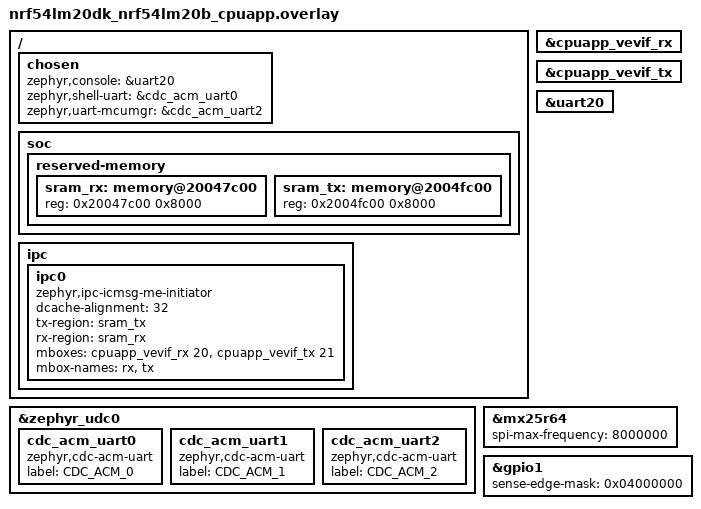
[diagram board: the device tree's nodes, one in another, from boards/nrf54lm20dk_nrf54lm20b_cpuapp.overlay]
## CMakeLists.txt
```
#
# Copyright (c) 2022 Nordic Semiconductor ASA
#
# SPDX-License-Identifier: Apache-2.0
#

cmake_minimum_required(VERSION 3.20.0)

find_package(Zephyr REQUIRED HINTS $ENV{ZEPHYR_BASE})

project(ipc_service)

FILE(GLOB app_sources src/*.c)
target_sources(app PRIVATE ${app_sources})

zephyr_include_directories(include memfault_config)
```

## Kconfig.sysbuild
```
# Copyright 2023 Nordic Semiconductor ASA
#
# SPDX-License-Identifier: Apache-2.0

source "share/sysbuild/Kconfig"

config NET_CORE_BOARD
string
	default "$(BOARD)/nrf5340/cpunet" if $(BOARD) = "nrf5340dk"
	default "$(BOARD)/nrf5340/cpunet" if $(BOARD) = "nrf5340bsim"
	default "$(BOARD)/nrf54h20/cpurad" if $(BOARD) = "nrf54h20dk"
	default "nrf54lm20dk/nrf54lm20b/cpuflpr" if "$(BOARD)/$(BOARD_QUALIFIERS)" = "nrf54lm20dk/nrf54lm20b/cpuapp"
```

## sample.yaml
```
sample:
  name: IPC multi-endpoint MDS + FLPR
common:
  sysbuild: true
  extra_args: multi_endpoint_SNIPPET="nordic-flpr;mds-flpr"
  tags: ipc bluetooth mcuboot mcumgr
tests:
  sample.ipc.multi_endpoint.mds_flpr.nrf54lm20b:
    platform_allow:
      - nrf54lm20dk/nrf54lm20b/cpuapp
    integration_platforms:
      - nrf54lm20dk/nrf54lm20b/cpuapp
    harness: console
    harness_config:
      type: multi_line
      ordered: false
      regex:
        - "Starting Bluetooth Memfault sample with FLPR IPC"
        - "APP version:"
        - "Bluetooth initialized"
        - "Advertising successfully started"
    timeout: 60

  sample.ipc.multi_endpoint.mds_flpr.nrf54lm20b.build:
    platform_allow:
      - nrf54lm20dk/nrf54lm20b/cpuapp
    integration_platforms:
      - nrf54lm20dk/nrf54lm20b/cpuapp
    build_only: true
    timeout: 600

  sample.ipc.multi_endpoint.mds_flpr.nrf54lm20b.ota_ble:
    platform_allow:
      - nrf54lm20dk/nrf54lm20b/cpuapp
    integration_platforms:
      - nrf54lm20dk/nrf54lm20b/cpuapp
    harness: pytest
    harness_config:
      fixture: usb_hci
      pytest_root:
        - "pytest/test_ota_ble.py"
    slow: true
    timeout: 600
```

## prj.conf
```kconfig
CONFIG_NCS_SAMPLES_DEFAULTS=y

CONFIG_PRINTK=y

CONFIG_IPC_SERVICE=y
CONFIG_MBOX=y
CONFIG_IPC_SERVICE_LOG_LEVEL_INF=y

CONFIG_BT=y
# BT shell for bt advertise / id-show / etc. Connection dumps used to wedge CDC0
# shell (IRQ TXDONE wait forever). Mitigations below: blocking shell TX + CDC WQ.
CONFIG_BT_SHELL=y
CONFIG_BT_SMP=y
CONFIG_BT_PERIPHERAL=y
CONFIG_BT_DEVICE_NAME="Nordic_Memfault"
CONFIG_BT_PRIVACY=y
# Advertise with identity address (see BT_LE_ADV_OPT_USE_IDENTITY in main.c) so
# scanners see a stable MAC; privacy IRK still used once bonded.
# Allow Windows/bleak to re-pair over an existing Just Works bond (repair after
# remove-on-host or stale LTK) without requiring bt clear all on the DK.
CONFIG_BT_SMP_ALLOW_UNAUTH_OVERWRITE=y
# Windows/iOS Just Works bonding (no display/keyboard). MITM enforcement rejects
# that pairing so bonds do not stick and phones treat each connect as a new device.
CONFIG_BT_SMP_ENFORCE_MITM=n

CONFIG_BT_BAS=y
CONFIG_BT_MDS=y

CONFIG_BT_CTLR_PHY_2M=y
CONFIG_BT_BUF_ACL_RX_SIZE=251
CONFIG_BT_L2CAP_TX_MTU=247
CONFIG_BT_BUF_ACL_TX_SIZE=251
CONFIG_BT_CTLR_DATA_LENGTH_MAX=251

CONFIG_LOG=y
CONFIG_LOG_PRINTK=n
CONFIG_LOG_DEFAULT_LEVEL=2
CONFIG_LOG_MODE_DEFERRED=y
CONFIG_LOG_MODE_OVERFLOW=y
CONFIG_LOG_BACKEND_RTT=n

CONFIG_SHELL=y
CONFIG_SENSOR_SHELL=n
CONFIG_DK_LIBRARY=y
# Keep bt_shell usable on CDC0: blocking TX avoids forever wait on UART IRQ
# TXDONE when BT conn callbacks print Connected/LMP/Features into the shell.
CONFIG_SHELL_BACKEND_SERIAL_FORCE_TX_BLOCKING_MODE=y
CONFIG_SHELL_BACKEND_SERIAL_TX_RING_BUFFER_SIZE=256

CONFIG_HEAP_MEM_POOL_SIZE=8192

CONFIG_MEMFAULT=y
CONFIG_MEMFAULT_SHELL=y
CONFIG_MEMFAULT_LOGGING_ENABLE=y
CONFIG_MEMFAULT_LOG_LEVEL_INF=y

CONFIG_MEMFAULT_NCS_PROJECT_KEY="PRDDdY3Idi9MqFBLK1U11AyuNoZoaqPj"
CONFIG_MEMFAULT_NCS_DEVICE_ID_STATIC=y
CONFIG_MEMFAULT_NCS_DEVICE_ID="nrf-ble-testdevice"
# Firmware version comes from the sample VERSION file (APP_VERSION_TWEAK_STRING).
CONFIG_MEMFAULT_NCS_FW_VERSION_STATIC=y
CONFIG_MEMFAULT_NCS_BT_METRICS=y
CONFIG_MEMFAULT_MCUMGR_GRP=y

CONFIG_BT_SETTINGS=y
CONFIG_FLASH=y
CONFIG_FLASH_PAGE_LAYOUT=y
CONFIG_FLASH_MAP=y
CONFIG_SETTINGS=y
# nRF54L Series: use ZMS (not NVS) as the Settings backend for bonding/CCCs.
CONFIG_ZMS=y
CONFIG_SETTINGS_ZMS=y

# SPI00 MX25R64 for spiflash CLI (OTA secondary remains on internal RRAM)
CONFIG_GPIO=y
CONFIG_SPI=y
CONFIG_SPI_NOR=y
CONFIG_SPI_NOR_FLASH_LAYOUT_PAGE_SIZE=4096
CONFIG_NORDIC_QSPI_NOR=n

# Sleep shell: System OFF + reset-cause decode + device suspend before off
CONFIG_POWEROFF=y
CONFIG_HWINFO=y
CONFIG_PM_DEVICE=y

# BLE + UART MCUmgr OTA (same coupled app_update.bin).
# UART SMP is on USB CDC2 only; CDC1 stays FLPR logs.
CONFIG_NCS_SAMPLE_MCUMGR_BT_OTA_DFU=y
CONFIG_NCS_SAMPLE_MCUMGR_BT_OTA_DFU_SPEEDUP=y
CONFIG_MCUMGR_GRP_ZBASIC_STORAGE_ERASE=n
# CONFIG_MCUBOOT_IMGTOOL_SIGN_VERSION defaults to APP_VERSION_TWEAK_STRING from VERSION.
CONFIG_UART_MCUMGR=y
CONFIG_MCUMGR_TRANSPORT_UART=y
# Larger UART SMP frames + more line buffers so USB CDC DFU does not stall when
# the host fills NETBUF-sized chunks (default RX was 128*2).
CONFIG_MCUMGR_TRANSPORT_UART_MTU=1024
CONFIG_UART_MCUMGR_RX_BUF_SIZE=128
CONFIG_UART_MCUMGR_RX_BUF_COUNT=16
CONFIG_BASE64=y

# Triple CDC ACM (USB device on cpuapp). Stock CDC_ACM_SERIAL_* boot helper
# is off — src/usb_cdc_triple.c registers CDC0/1/2 explicitly.
CONFIG_SERIAL=y
CONFIG_CONSOLE=y
CONFIG_UART_CONSOLE=y
CONFIG_UART_LINE_CTRL=y
CONFIG_USB_DEVICE_STACK_NEXT=y
CONFIG_USBD_CDC_ACM_CLASS=y
CONFIG_CDC_ACM_SERIAL_INITIALIZE_AT_BOOT=n
# Dedicated CDC workqueue so shell/BT prints do not deadlock the USB path.
CONFIG_USBD_CDC_ACM_WORKQUEUE=y
CONFIG_USBD_CDC_ACM_STACK_SIZE=2048
# Host control transfers can request up to ~4 KiB (seen as udc alloc 4095 on ep 0x80).
# Three CDCs need more outstanding request buffers than dual-CDC defaults.
CONFIG_UDC_BUF_POOL_SIZE=12288
CONFIG_UDC_BUF_COUNT=48
```

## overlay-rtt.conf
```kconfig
# Optional: free uart20 - printk/boot on RTT; shell + LOG stay on USB CDC0.
# Use with boards/nrf54lm20dk_nrf54lm20b_cpuapp_rtt.overlay (see just build-rtt).

CONFIG_USE_SEGGER_RTT=y
CONFIG_RTT_CONSOLE=y
CONFIG_UART_CONSOLE=n

# Do not block boot if no RTT Viewer is attached (default mode is skip).
CONFIG_SEGGER_RTT_MODE_NO_BLOCK_SKIP=y
# Avoid sleep/retry delays when the RTT host is absent.
CONFIG_RTT_TX_RETRY_CNT=0

# Keep printk on RTT; application LOG continues via shell backend on CDC0.
CONFIG_LOG_BACKEND_RTT=n
CONFIG_LOG_PRINTK=n
```

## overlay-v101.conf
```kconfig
# Deprecated: bump the sample VERSION file instead (VERSION_MAJOR/MINOR/PATCHLEVEL/TWEAK).
# Kept empty so older docs/scripts that still pass EXTRA_CONF_FILE=overlay-v101.conf do not fail.
```

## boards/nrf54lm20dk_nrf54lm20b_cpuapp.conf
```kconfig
# SPI00 MX25R64 (jedec,spi-nor) — plain SPI, not SQSPI
CONFIG_GPIO=y
CONFIG_SPI=y
CONFIG_SPI_NOR=y
CONFIG_SPI_NOR_FLASH_LAYOUT_PAGE_SIZE=4096
CONFIG_NORDIC_QSPI_NOR=n
```

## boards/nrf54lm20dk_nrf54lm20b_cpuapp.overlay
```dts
/ {
	chosen {
		/*
		 * App printk/LOG → debugger VCOM (uart20).
		 * USB CDC0 → shell
		 * USB CDC1 → FLPR log forward (see flpr_ipc.c)
		 * USB CDC2 → MCUmgr UART SMP DFU (CONFIG_MCUMGR_TRANSPORT_UART)
		 *
		 * Stock cdc_acm_serial boot helper only registers chosen CDCs;
		 * this sample uses src/usb_cdc_triple.c so CDC1 is registered
		 * even though it is not a chosen backend.
		 */
		zephyr,console = &uart20;
		zephyr,shell-uart = &cdc_acm_uart0;
		zephyr,uart-mcumgr = &cdc_acm_uart2;
	};

	soc {
		reserved-memory {
			#address-cells = <1>;
			#size-cells = <1>;

			sram_rx: memory@20047c00 {
				reg = <0x20047c00 0x8000>;
			};

			sram_tx: memory@2004fc00 {
				reg = <0x2004fc00 0x8000>;
			};
		};
	};

	ipc {
		ipc0: ipc0 {
			compatible = "zephyr,ipc-icmsg-me-initiator";
			dcache-alignment = <32>;
			tx-region = <&sram_tx>;
			rx-region = <&sram_rx>;
			mboxes = <&cpuapp_vevif_rx 20>, <&cpuapp_vevif_tx 21>;
			mbox-names = "rx", "tx";
			status = "okay";
		};
	};
};

&cpuapp_vevif_rx {
	status = "okay";
};

&cpuapp_vevif_tx {
	status = "okay";
};

&uart20 {
	status = "okay";
};

&zephyr_udc0 {
	cdc_acm_uart0: cdc_acm_uart0 {
		compatible = "zephyr,cdc-acm-uart";
		label = "CDC_ACM_0";
	};

	cdc_acm_uart1: cdc_acm_uart1 {
		compatible = "zephyr,cdc-acm-uart";
		label = "CDC_ACM_1";
	};

	cdc_acm_uart2: cdc_acm_uart2 {
		compatible = "zephyr,cdc-acm-uart";
		label = "CDC_ACM_2";
	};
};

/* SPI00 MX25R64 for shell CLI only — OTA secondary stays on internal RRAM. */
&mx25r64 {
	status = "okay";
	spi-max-frequency = <8000000>;
};

/* Button0 (sw0) on P1.26 — PORT sense for System OFF / idle GPIO wake. */
&gpio1 {
	sense-edge-mask = <0x04000000>; /* BIT(26) */
};
```

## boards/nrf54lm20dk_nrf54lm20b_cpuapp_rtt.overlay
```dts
/*
 * Optional RTT boot console - apply with overlay-rtt.conf (just build-rtt).
 *
 * - Disables debugger uart20 (frees the UART peripheral / pins)
 * - printk / early boot go to SEGGER RTT (no USB wait, non-blocking)
 * - Shell remains USB CDC0; FLPR logs CDC1; MCUmgr DFU CDC2
 *   (from nrf54lm20dk_nrf54lm20b_cpuapp.overlay)
 */

/ {
	chosen {
		/delete-property/ zephyr,console;
	};
};

&uart20 {
	status = "disabled";
};
```

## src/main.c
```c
#include "flpr_ipc.h"
#include "sleep_shell.h"

#include <zephyr/kernel.h>
#include <zephyr/dfu/mcuboot.h>

#include <zephyr/bluetooth/bluetooth.h>
#include <zephyr/bluetooth/conn.h>
#include <zephyr/bluetooth/hci.h>
#include <zephyr/bluetooth/services/bas.h>

#include <bluetooth/services/mds.h>

#include <zephyr/settings/settings.h>

#include <dk_buttons_and_leds.h>

#include <memfault/metrics/metrics.h>
#include <memfault/core/trace_event.h>

#define DEVICE_NAME     CONFIG_BT_DEVICE_NAME
#define DEVICE_NAME_LEN (sizeof(DEVICE_NAME) - 1)

#define RUN_STATUS_LED DK_LED1
#define CON_STATUS_LED DK_LED2

#define RUN_LED_BLINK_INTERVAL 1000

/* Stable advertiser address so nRF Connect / Memfault see the same device after
 * disconnect (default privacy RPA rotation looks like a new peripheral).
 */
static const struct bt_le_adv_param *const adv_param =
	BT_LE_ADV_PARAM(BT_LE_ADV_OPT_CONN | BT_LE_ADV_OPT_USE_IDENTITY,
			BT_GAP_ADV_FAST_INT_MIN_2, BT_GAP_ADV_FAST_INT_MAX_2, NULL);

static const struct bt_data ad[] = {
	BT_DATA_BYTES(BT_DATA_FLAGS, (BT_LE_AD_GENERAL | BT_LE_AD_NO_BREDR)),
	BT_DATA_BYTES(BT_DATA_UUID128_ALL, BT_UUID_MDS_VAL),
};

static const struct bt_data sd[] = {
	BT_DATA(BT_DATA_NAME_COMPLETE, DEVICE_NAME, DEVICE_NAME_LEN),
};

static struct bt_conn *mds_conn;
static struct k_work adv_work;

static void bas_work_handler(struct k_work *work);

static K_WORK_DELAYABLE_DEFINE(bas_work, bas_work_handler);

static void security_changed(struct bt_conn *conn, bt_security_t level,
			     enum bt_security_err err)
{
	char addr[BT_ADDR_LE_STR_LEN];

	bt_addr_le_to_str(bt_conn_get_dst(conn), addr, sizeof(addr));

	if (!err) {
		printk("Security changed: %s level %u\n", addr, level);
	} else {
		printk("Security failed: %s level %u err %d %s\n", addr, level, err,
		       bt_security_err_to_str(err));
	}

	if (level >= BT_SECURITY_L2) {
		if (!mds_conn) {
			mds_conn = conn;
		}
	}
}

static void adv_work_handler(struct k_work *work)
{
	int err = bt_le_adv_start(adv_param, ad, ARRAY_SIZE(ad), sd, ARRAY_SIZE(sd));

	if (err) {
		printk("Advertising failed to start (err %d)\n", err);
		return;
	}

	printk("Advertising successfully started\n");
}

static void advertising_start(void)
{
	k_work_submit(&adv_work);
}

static void disconnected(struct bt_conn *conn, uint8_t reason)
{
	printk("Disconnected, reason 0x%02x %s\n", reason, bt_hci_err_to_str(reason));

	dk_set_led_off(CON_STATUS_LED);

	if (conn == mds_conn) {
		mds_conn = NULL;
	}
	/* Do not restart advertising here: with CONFIG_BT_MAX_CONN=1 the conn
	 * object is still held until recycled_cb(). That is where we advertise.
	 */
}

static void recycled_cb(void)
{
	printk("Connection object available from previous conn. Disconnect is complete!\n");
	advertising_start();
}

static void connected(struct bt_conn *conn, uint8_t conn_err)
{
	char addr[BT_ADDR_LE_STR_LEN];

	if (conn_err) {
		printk("Connection failed, err 0x%02x %s\n", conn_err, bt_hci_err_to_str(conn_err));
		/* Failed connect still frees the slot via recycled → advertising. */
		return;
	}

	bt_addr_le_to_str(bt_conn_get_dst(conn), addr, sizeof(addr));
	printk("Connected %s\n", addr);

	dk_set_led_on(CON_STATUS_LED);
}

BT_CONN_CB_DEFINE(conn_callbacks) = {
	.connected        = connected,
	.disconnected     = disconnected,
	.security_changed = security_changed,
	.recycled         = recycled_cb,
};

static void pairing_complete(struct bt_conn *conn, bool bonded)
{
	char addr[BT_ADDR_LE_STR_LEN];

	bt_addr_le_to_str(bt_conn_get_dst(conn), addr, sizeof(addr));

	printk("Pairing completed: %s, bonded: %d\n", addr, bonded);
}

static void pairing_failed(struct bt_conn *conn, enum bt_security_err reason)
{
	char addr[BT_ADDR_LE_STR_LEN];

	bt_addr_le_to_str(bt_conn_get_dst(conn), addr, sizeof(addr));

	printk("Pairing failed conn: %s, reason %d %s\n", addr, reason,
	       bt_security_err_to_str(reason));
}

static struct bt_conn_auth_info_cb conn_auth_info_callbacks = {
	.pairing_complete = pairing_complete,
	.pairing_failed = pairing_failed
};

static void auth_cancel(struct bt_conn *conn)
{
	char addr[BT_ADDR_LE_STR_LEN];

	bt_addr_le_to_str(bt_conn_get_dst(conn), addr, sizeof(addr));

	printk("Pairing cancelled: %s\n", addr);
}

static struct bt_conn_auth_cb conn_auth_callbacks = {
	.cancel = auth_cancel,
};

static bool mds_access_enable(struct bt_conn *conn)
{
	if (mds_conn && (conn == mds_conn)) {
		return true;
	}

	return false;
}

static const struct bt_mds_cb mds_cb = {
	.access_enable = mds_access_enable,
};

static void button_handler(uint32_t button_state, uint32_t has_changed)
{
	static bool time_measure_start;

	int err;
	uint32_t buttons = button_state & has_changed;

	sleep_shell_button_notify(buttons);

	if (buttons & DK_BTN1_MSK) {
		time_measure_start = !time_measure_start;

		if (time_measure_start) {
			err = MEMFAULT_METRIC_TIMER_START(button_elapsed_time_ms);
			if (err) {
				printk("Failed to start memfault metrics timer: %d\n", err);
			}
		} else {
			err = MEMFAULT_METRIC_TIMER_STOP(button_elapsed_time_ms);
			if (err) {
				printk("Failed to stop memfault metrics: %d\n", err);
			}

			memfault_metrics_heartbeat_debug_trigger();
		}
	}

	if (has_changed & DK_BTN2_MSK) {
		bool pressed = (buttons & DK_BTN2_MSK) ? 1 : 0;

		MEMFAULT_TRACE_EVENT_WITH_LOG(button_state_changed, "Button state: %u",
					      pressed);

		printk("button_state_changed event has been tracked, button state: %u\n",
		       pressed);
	}

	if (buttons & DK_BTN3_MSK) {
		err = MEMFAULT_METRIC_ADD(button_press_count, 1);
		if (err) {
			printk("Failed to increase button_press_count metric: %d\n", err);
		} else {
			printk("button_press_count metric increased\n");
		}
	}

	if (buttons & DK_BTN4_MSK) {
		volatile uint32_t i;

		printk("Division by zero will now be triggered\n");
#pragma GCC diagnostic push
#pragma GCC diagnostic ignored "-Wdiv-by-zero"
		i = 1 / 0;
#pragma GCC diagnostic pop
		ARG_UNUSED(i);
	}
}

static void bas_notify(void)
{
	int err;
	uint8_t battery_level = bt_bas_get_battery_level();

	__ASSERT_NO_MSG(battery_level > 0);

	battery_level--;

	if (battery_level == 0) {
		battery_level = 100U;
	}

	err = MEMFAULT_METRIC_SET_UNSIGNED(battery_soc_pct, battery_level);
	if (err) {
		printk("Failed to set battery_soc_pct memfault metrics (err %d)\n", err);
	}

	bt_bas_set_battery_level(battery_level);
}

static void bas_work_handler(struct k_work *work)
{
	if (!sleep_shell_is_quiesced()) {
		bas_notify();
	}
	k_work_reschedule((struct k_work_delayable *)work, K_SECONDS(1));
}

int main(void)
{
	uint32_t blink_status = 0;
	int err;
	size_t id_count = 1;
	bt_addr_le_t addrs[CONFIG_BT_ID_MAX];
	char addr_str[BT_ADDR_LE_STR_LEN];

	printk("Starting Bluetooth Memfault sample with FLPR IPC\n");
	printk("APP version: %s\n", CONFIG_MCUBOOT_IMGTOOL_SIGN_VERSION);
	sleep_shell_print_reset_cause();

	/* After MCUboot test-swap, confirm so secondary is free for the next A/B DFU.
	 * Without this, img_mgmt returns NO_FREE_SLOT until confirm or revert.
	 */
	if (!boot_is_img_confirmed()) {
		err = boot_write_img_confirmed();
		if (err) {
			printk("Failed to confirm MCUboot image (err %d)\n", err);
		} else {
			printk("MCUboot image confirmed (A/B slot freed)\n");
		}
	}

	err = dk_leds_init();
	if (err) {
		printk("LEDs init failed (err %d)\n", err);
		return 0;
	}

	err = dk_buttons_init(button_handler);
	if (err) {
		printk("Failed to initialize buttons (err %d)\n", err);
		return 0;
	}

	err = bt_mds_cb_register(&mds_cb);
	if (err) {
		printk("Memfault Diagnostic service callback registration failed (err %d)\n", err);
		return 0;
	}

	err = bt_enable(NULL);
	if (err) {
		printk("Bluetooth init failed (err %d)\n", err);
	} else {
		err = bt_conn_auth_cb_register(&conn_auth_callbacks);
		if (err) {
			printk("Failed to register authorization callbacks (err %d)\n", err);
			return 0;
		}

		err = bt_conn_auth_info_cb_register(&conn_auth_info_callbacks);
		if (err) {
			printk("Failed to register authorization info callbacks (err %d)\n", err);
			return 0;
		}

		printk("Bluetooth initialized\n");

		if (IS_ENABLED(CONFIG_SETTINGS)) {
			err = settings_load();
			if (err) {
				printk("Failed to load settings (err %d)\n", err);
				return 0;
			}
		}

		bt_id_get(addrs, &id_count);
		if (id_count > 0) {
			bt_addr_le_to_str(&addrs[0], addr_str, sizeof(addr_str));
			printk("Identity address (stable advertiser): %s\n", addr_str);
		}
	}

	err = flpr_ipc_init();
	if (err) {
		printk("FLPR IPC init failed (err %d), continuing without FLPR\n", err);
	}

	k_work_init(&adv_work, adv_work_handler);
	advertising_start();

	k_work_schedule(&bas_work, K_SECONDS(1));

	for (;;) {
		if (!sleep_shell_is_quiesced()) {
			dk_set_led(RUN_STATUS_LED, (++blink_status) % 2);
		} else {
			dk_set_led(RUN_STATUS_LED, 0);
		}
		k_sleep(K_MSEC(RUN_LED_BLINK_INTERVAL));
	}
}
```

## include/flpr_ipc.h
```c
#ifndef FLPR_IPC_H_
#define FLPR_IPC_H_

#include <stdbool.h>
#include <stddef.h>

#ifdef __cplusplus
extern "C" {
#endif

int flpr_ipc_init(void);

bool flpr_ipc_log_bound(void);
bool flpr_ipc_ctrl_bound(void);

int flpr_ipc_send_ping(void);
int flpr_ipc_request_stats(void);
int flpr_ipc_request_log(const char *text);

void flpr_ipc_set_echo(bool enable);
bool flpr_ipc_echo_enabled(void);

#ifdef __cplusplus
}
#endif

#endif /* FLPR_IPC_H_ */
```

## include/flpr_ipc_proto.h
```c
#ifndef FLPR_IPC_PROTO_H_
#define FLPR_IPC_PROTO_H_

#include <stdint.h>

#define FLPR_IPC_EPT_LOG_NAME  "flpr_log"
#define FLPR_IPC_EPT_CTRL_NAME "flpr_ctrl"

#define FLPR_CTRL_OPCODE_PING     0x01
#define FLPR_CTRL_OPCODE_PONG     0x02
#define FLPR_CTRL_OPCODE_STATS_REQ 0x03
#define FLPR_CTRL_OPCODE_STATS    0x04
#define FLPR_CTRL_OPCODE_LOG_REQ  0x05

struct flpr_ctrl_hdr {
	uint8_t opcode;
	uint8_t seq;
	uint16_t len;
} __packed;

struct flpr_stats {
	uint32_t uptime_ms;
	uint32_t heartbeat;
	uint32_t free_stack;
} __packed;

#define FLPR_LOG_MAX_LEN 120

#endif /* FLPR_IPC_PROTO_H_ */
```

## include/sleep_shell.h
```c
/*
 * Copyright (c) 2026 Nordic Semiconductor ASA
 * SPDX-License-Identifier: Apache-2.0
 */

#ifndef SLEEP_SHELL_H_
#define SLEEP_SHELL_H_

#include <stdbool.h>
#include <stdint.h>

#ifdef __cplusplus
extern "C" {
#endif

/** True while sleep idle/off prep has quiesced LED blink / BAS churn. */
bool sleep_shell_is_quiesced(void);

/**
 * Notify sleep idle wait of a DK button event (call from button_handler).
 * @param buttons Bitmask of newly pressed buttons (e.g. DK_BTN1_MSK).
 */
void sleep_shell_button_notify(uint32_t buttons);

/** Print decoded hwinfo reset cause (also used early at boot). */
void sleep_shell_print_reset_cause(void);

#ifdef __cplusplus
}
#endif

#endif /* SLEEP_SHELL_H_ */
```

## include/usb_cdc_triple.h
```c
/*
 * Copyright (c) 2026 Nordic Semiconductor ASA
 * SPDX-License-Identifier: Apache-2.0
 */

#ifndef USB_CDC_TRIPLE_H_
#define USB_CDC_TRIPLE_H_

#ifdef __cplusplus
extern "C" {
#endif

/** Disable the triple-CDC USBD stack (for System OFF entry). */
int usb_cdc_triple_disable(void);

#ifdef __cplusplus
}
#endif

#endif /* USB_CDC_TRIPLE_H_ */
```

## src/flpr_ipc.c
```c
#include "flpr_ipc.h"
#include "flpr_ipc_proto.h"

#include <string.h>

#include <zephyr/device.h>
#include <zephyr/drivers/uart.h>
#include <zephyr/ipc/ipc_service.h>
#include <zephyr/kernel.h>
#include <zephyr/logging/log.h>
#include <zephyr/sys/printk.h>

#include <memfault/metrics/metrics.h>

LOG_MODULE_REGISTER(flpr_ipc, CONFIG_LOG_DEFAULT_LEVEL);

static const struct device *ipc0_dev;
static struct ipc_ept ept_log;
static struct ipc_ept ept_ctrl;

static K_SEM_DEFINE(log_bound_sem, 0, 1);
static K_SEM_DEFINE(ctrl_bound_sem, 0, 1);
static K_SEM_DEFINE(pong_sem, 0, 1);

static volatile bool log_bound;
static volatile bool ctrl_bound;
static volatile bool echo_enabled;
static volatile uint8_t last_pong_seq;

static const struct device *cdc1_dev;

static void maybe_write_cdc1(const void *data, size_t len)
{
	if (cdc1_dev == NULL || !device_is_ready(cdc1_dev)) {
		return;
	}

	const uint8_t *p = data;

	for (size_t i = 0; i < len; i++) {
		uart_poll_out(cdc1_dev, p[i]);
	}
}

static void ept_log_bound(void *priv)
{
	ARG_UNUSED(priv);
	log_bound = true;
	k_sem_give(&log_bound_sem);
	/* #region agent log */
	printk("IPC[A] BOUND flpr_log @ %u ms\n", k_uptime_get_32());
	/* #endregion */
	printk("FLPR IPC: flpr_log bound\n");
}

static void ept_ctrl_bound(void *priv)
{
	ARG_UNUSED(priv);
	ctrl_bound = true;
	k_sem_give(&ctrl_bound_sem);
	/* #region agent log */
	printk("IPC[A] BOUND flpr_ctrl @ %u ms\n", k_uptime_get_32());
	/* #endregion */
	printk("FLPR IPC: flpr_ctrl bound\n");
}

static void ept_log_recv(const void *data, size_t len, void *priv)
{
	ARG_UNUSED(priv);

	if (len == 0 || data == NULL) {
		return;
	}

	maybe_write_cdc1(data, len);
	/* Windows CDC hosts expect CRLF; LF-only leaves the cursor mid-line. */
	maybe_write_cdc1("\r\n", 2);

	if (echo_enabled) {
		printk("[FLPR LOG] %.*s\n", (int)len, (const char *)data);
	}
}

static void handle_stats(const struct flpr_stats *stats)
{
	int err;

	err = MEMFAULT_METRIC_SET_UNSIGNED(flpr_uptime_ms, stats->uptime_ms);
	if (err) {
		LOG_WRN("flpr_uptime_ms set failed: %d", err);
	}

	err = MEMFAULT_METRIC_SET_UNSIGNED(flpr_heartbeat, stats->heartbeat);
	if (err) {
		LOG_WRN("flpr_heartbeat set failed: %d", err);
	}

	err = MEMFAULT_METRIC_SET_UNSIGNED(flpr_free_stack, stats->free_stack);
	if (err) {
		LOG_WRN("flpr_free_stack set failed: %d", err);
	}

	if (echo_enabled) {
		printk("[FLPR STATS] uptime=%u hb=%u stack=%u\n", stats->uptime_ms,
		       stats->heartbeat, stats->free_stack);
	}
}

static void ept_ctrl_recv(const void *data, size_t len, void *priv)
{
	ARG_UNUSED(priv);

	if (data == NULL || len < sizeof(struct flpr_ctrl_hdr)) {
		return;
	}

	const struct flpr_ctrl_hdr *hdr = data;
	const uint8_t *payload = (const uint8_t *)data + sizeof(*hdr);
	size_t payload_len = len - sizeof(*hdr);

	if (hdr->len > payload_len) {
		return;
	}

	switch (hdr->opcode) {
	case FLPR_CTRL_OPCODE_PONG:
		last_pong_seq = hdr->seq;
		k_sem_give(&pong_sem);
		if (echo_enabled) {
			printk("[FLPR CTRL] pong seq=%u\n", hdr->seq);
		}
		break;
	case FLPR_CTRL_OPCODE_STATS:
		if (hdr->len >= sizeof(struct flpr_stats)) {
			struct flpr_stats stats;

			memcpy(&stats, payload, sizeof(stats));
			handle_stats(&stats);
		}
		break;
	default:
		if (echo_enabled) {
			printk("[FLPR CTRL] opcode=0x%02x len=%u\n", hdr->opcode, hdr->len);
		}
		break;
	}
}

static struct ipc_ept_cfg ept_log_cfg = {
	.name = FLPR_IPC_EPT_LOG_NAME,
	.cb = {
		.bound = ept_log_bound,
		.received = ept_log_recv,
	},
};

static struct ipc_ept_cfg ept_ctrl_cfg = {
	.name = FLPR_IPC_EPT_CTRL_NAME,
	.cb = {
		.bound = ept_ctrl_bound,
		.received = ept_ctrl_recv,
	},
};

static int send_ctrl(uint8_t opcode, uint8_t seq, const void *payload, uint16_t payload_len)
{
	uint8_t buf[sizeof(struct flpr_ctrl_hdr) + FLPR_LOG_MAX_LEN];
	struct flpr_ctrl_hdr *hdr = (struct flpr_ctrl_hdr *)buf;

	if (!ctrl_bound) {
		return -ENOTCONN;
	}

	if (payload_len > FLPR_LOG_MAX_LEN) {
		return -EINVAL;
	}

	hdr->opcode = opcode;
	hdr->seq = seq;
	hdr->len = payload_len;

	if (payload_len && payload != NULL) {
		memcpy(buf + sizeof(*hdr), payload, payload_len);
	}

	return ipc_service_send(&ept_ctrl, buf, sizeof(*hdr) + payload_len);
}

int flpr_ipc_init(void)
{
	int ret;
	uint32_t t0;

#if DT_NODE_EXISTS(DT_NODELABEL(cdc_acm_uart1))
	cdc1_dev = DEVICE_DT_GET(DT_NODELABEL(cdc_acm_uart1));
#endif

	/* #region agent log */
	printk("IPC[A] init enter @ %u ms\n", k_uptime_get_32());
	/* #endregion */

	ipc0_dev = DEVICE_DT_GET(DT_NODELABEL(ipc0));
	if (!device_is_ready(ipc0_dev)) {
		printk("FLPR IPC: ipc0 not ready\n");
		return -ENODEV;
	}

	/* #region agent log */
	printk("IPC[A] open_instance enter @ %u ms\n", k_uptime_get_32());
	/* #endregion */
	ret = ipc_service_open_instance(ipc0_dev);
	/* #region agent log */
	printk("IPC[A] open_instance ret=%d @ %u ms\n", ret, k_uptime_get_32());
	/* #endregion */
	if (ret < 0 && ret != -EALREADY) {
		printk("FLPR IPC: open failed (%d)\n", ret);
		return ret;
	}

	t0 = k_uptime_get_32();
	/* #region agent log */
	printk("IPC[A] register flpr_log enter @ %u ms\n", t0);
	/* #endregion */
	ret = ipc_service_register_endpoint(ipc0_dev, &ept_log, &ept_log_cfg);
	/* #region agent log */
	printk("IPC[A] register flpr_log ret=%d dt=%u ms\n", ret, k_uptime_get_32() - t0);
	/* #endregion */
	if (ret < 0) {
		printk("FLPR IPC: register flpr_log failed (%d)\n", ret);
		return ret;
	}

	t0 = k_uptime_get_32();
	/* #region agent log */
	printk("IPC[A] register flpr_ctrl enter @ %u ms\n", t0);
	/* #endregion */
	ret = ipc_service_register_endpoint(ipc0_dev, &ept_ctrl, &ept_ctrl_cfg);
	/* #region agent log */
	printk("IPC[A] register flpr_ctrl ret=%d dt=%u ms\n", ret, k_uptime_get_32() - t0);
	/* #endregion */
	if (ret < 0) {
		printk("FLPR IPC: register flpr_ctrl failed (%d)\n", ret);
		return ret;
	}

	/* Do not block forever; FLPR may bind slightly later. */
	/* #region agent log */
	printk("IPC[A] sem log wait enter @ %u ms\n", k_uptime_get_32());
	/* #endregion */
	ret = k_sem_take(&log_bound_sem, K_MSEC(3000));
	/* #region agent log */
	printk("IPC[A] sem log ret=%d bound=%d @ %u ms\n", ret, log_bound, k_uptime_get_32());
	/* #endregion */

	/* #region agent log */
	printk("IPC[A] sem ctrl wait enter @ %u ms\n", k_uptime_get_32());
	/* #endregion */
	ret = k_sem_take(&ctrl_bound_sem, K_MSEC(3000));
	/* #region agent log */
	printk("IPC[A] sem ctrl ret=%d bound=%d @ %u ms\n", ret, ctrl_bound, k_uptime_get_32());
	/* #endregion */

	printk("FLPR IPC: init done (log_bound=%d ctrl_bound=%d)\n", log_bound, ctrl_bound);

	/* #region agent log */
	k_sleep(K_SECONDS(5));
	printk("IPC[A] late status log=%d ctrl=%d @ %u ms\n", log_bound, ctrl_bound,
	       k_uptime_get_32());
	/* #endregion */

	return 0;
}

bool flpr_ipc_log_bound(void)
{
	return log_bound;
}

bool flpr_ipc_ctrl_bound(void)
{
	return ctrl_bound;
}

int flpr_ipc_send_ping(void)
{
	static uint8_t seq;
	int ret;

	k_sem_reset(&pong_sem);
	seq++;
	ret = send_ctrl(FLPR_CTRL_OPCODE_PING, seq, NULL, 0);
	if (ret < 0) {
		return ret;
	}

	ret = k_sem_take(&pong_sem, K_MSEC(1000));
	if (ret < 0) {
		return ret;
	}

	if (last_pong_seq != seq) {
		return -EIO;
	}

	return 0;
}

int flpr_ipc_request_stats(void)
{
	return send_ctrl(FLPR_CTRL_OPCODE_STATS_REQ, 0, NULL, 0);
}

int flpr_ipc_request_log(const char *text)
{
	size_t len;

	if (text == NULL) {
		return -EINVAL;
	}

	len = strlen(text);
	if (len == 0) {
		return -EINVAL;
	}
	if (len > FLPR_LOG_MAX_LEN) {
		len = FLPR_LOG_MAX_LEN;
	}

	return send_ctrl(FLPR_CTRL_OPCODE_LOG_REQ, 0, text, (uint16_t)len);
}

void flpr_ipc_set_echo(bool enable)
{
	echo_enabled = enable;
}

bool flpr_ipc_echo_enabled(void)
{
	return echo_enabled;
}
```

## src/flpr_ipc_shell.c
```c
#include "flpr_ipc.h"

#include <stdlib.h>
#include <string.h>

#include <zephyr/shell/shell.h>

static int cmd_status(const struct shell *sh, size_t argc, char **argv)
{
	ARG_UNUSED(argc);
	ARG_UNUSED(argv);

	shell_print(sh, "flpr_log  bound: %s", flpr_ipc_log_bound() ? "yes" : "no");
	shell_print(sh, "flpr_ctrl bound: %s", flpr_ipc_ctrl_bound() ? "yes" : "no");
	shell_print(sh, "echo: %s", flpr_ipc_echo_enabled() ? "on" : "off");
	return 0;
}

static int cmd_ping(const struct shell *sh, size_t argc, char **argv)
{
	int ret;

	ARG_UNUSED(argc);
	ARG_UNUSED(argv);

	ret = flpr_ipc_send_ping();
	if (ret < 0) {
		shell_error(sh, "ping failed (%d)", ret);
		return ret;
	}

	shell_print(sh, "pong ok");
	return 0;
}

static int cmd_stats(const struct shell *sh, size_t argc, char **argv)
{
	int ret;

	ARG_UNUSED(argc);
	ARG_UNUSED(argv);

	ret = flpr_ipc_request_stats();
	if (ret < 0) {
		shell_error(sh, "stats request failed (%d)", ret);
		return ret;
	}

	shell_print(sh, "stats requested");
	return 0;
}

static int cmd_log(const struct shell *sh, size_t argc, char **argv)
{
	int ret;

	if (argc < 2) {
		shell_error(sh, "usage: flpr log <text>");
		return -EINVAL;
	}

	ret = flpr_ipc_request_log(argv[1]);
	if (ret < 0) {
		shell_error(sh, "log request failed (%d)", ret);
		return ret;
	}

	shell_print(sh, "log requested");
	return 0;
}

static int cmd_echo(const struct shell *sh, size_t argc, char **argv)
{
	if (argc < 2) {
		shell_print(sh, "echo is %s", flpr_ipc_echo_enabled() ? "on" : "off");
		return 0;
	}

	if (strcmp(argv[1], "on") == 0) {
		flpr_ipc_set_echo(true);
	} else if (strcmp(argv[1], "off") == 0) {
		flpr_ipc_set_echo(false);
	} else {
		shell_error(sh, "usage: flpr echo on|off");
		return -EINVAL;
	}

	shell_print(sh, "echo %s", argv[1]);
	return 0;
}

SHELL_STATIC_SUBCMD_SET_CREATE(flpr_cmds,
	SHELL_CMD(status, NULL, "Show FLPR IPC bind state", cmd_status),
	SHELL_CMD(ping, NULL, "Ping FLPR over flpr_ctrl", cmd_ping),
	SHELL_CMD(stats, NULL, "Request FLPR stats", cmd_stats),
	SHELL_CMD_ARG(log, NULL, "Request FLPR log line", cmd_log, 2, 0),
	SHELL_CMD_ARG(echo, NULL, "Echo FLPR RX to console: on|off", cmd_echo, 1, 1),
	SHELL_SUBCMD_SET_END
);

SHELL_CMD_REGISTER(flpr, &flpr_cmds, "FLPR IPC test commands", NULL);
```

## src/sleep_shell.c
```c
/*
 * Copyright (c) 2026 Nordic Semiconductor ASA
 * SPDX-License-Identifier: Apache-2.0
 *
 * Shell commands to exercise nRF54LM20 System ON idle (CDC/button wake)
 * and System OFF (GPIO DETECT / GRTC wake → reset).
 */

#include "sleep_shell.h"
#include "usb_cdc_triple.h"

#include <stdlib.h>
#include <string.h>

#include <zephyr/bluetooth/bluetooth.h>
#include <zephyr/bluetooth/conn.h>
#include <zephyr/bluetooth/hci.h>
#include <zephyr/device.h>
#include <zephyr/drivers/gpio.h>
#include <zephyr/drivers/hwinfo.h>
#include <zephyr/drivers/timer/nrf_grtc_timer.h>
#include <zephyr/kernel.h>
#include <zephyr/pm/device.h>
#include <zephyr/shell/shell.h>
#include <zephyr/sys/atomic.h>
#include <zephyr/sys/poweroff.h>
#include <zephyr/sys/printk.h>
#include <zephyr/sys/util.h>

#include <hal/nrf_power.h>

#include <dk_buttons_and_leds.h>

enum sleep_wake_src {
	SLEEP_WAKE_NONE = 0,
	SLEEP_WAKE_UART,
	SLEEP_WAKE_GPIO,
};

static atomic_t quiesced;
static enum sleep_wake_src wake_src;
static const struct shell *idle_sh;
static const struct gpio_dt_spec sw0 = GPIO_DT_SPEC_GET(DT_ALIAS(sw0), gpios);

bool sleep_shell_is_quiesced(void)
{
	return atomic_get(&quiesced) != 0;
}

static void set_quiesced(bool on)
{
	atomic_set(&quiesced, on ? 1 : 0);
}

static void idle_finish(const struct shell *sh)
{
	/* Only one wake path may complete (CDC bypass vs Button0). */
	if (!atomic_cas(&quiesced, 1, 0)) {
		return;
	}

	shell_set_bypass(sh, NULL, NULL);
	idle_sh = NULL;

	if (wake_src == SLEEP_WAKE_UART) {
		shell_print(sh, "Woke from System ON idle (source: uart)");
	} else if (wake_src == SLEEP_WAKE_GPIO) {
		shell_print(sh, "Woke from System ON idle (source: gpio)");
	} else {
		shell_print(sh, "Woke from System ON idle (source: unknown)");
	}
}

void sleep_shell_button_notify(uint32_t buttons)
{
	if (!sleep_shell_is_quiesced()) {
		return;
	}

	if (buttons & DK_BTN1_MSK) {
		const struct shell *sh = idle_sh;

		wake_src = SLEEP_WAKE_GPIO;
		if (sh != NULL) {
			idle_finish(sh);
		}
	}
}

void sleep_shell_print_reset_cause(void)
{
	uint32_t cause = 0;
	uint32_t supported = 0;
	int err;

	err = hwinfo_get_reset_cause(&cause);
	if (err) {
		printk("Reset cause: unavailable (%d)\n", err);
		return;
	}

	err = hwinfo_get_supported_reset_cause(&supported);
	if (err) {
		printk("Reset cause: 0x%08x (supported query failed %d)\n", cause, err);
		return;
	}

	printk("Reset cause: 0x%08x", cause);
	if (cause & supported & RESET_DEBUG) {
		printk(" (debugger)");
	} else if (cause & supported & RESET_CLOCK) {
		printk(" (System OFF wake: GRTC)");
	} else if (cause & supported & RESET_LOW_POWER_WAKE) {
		printk(" (System OFF wake: GPIO)");
	} else if (cause & supported & RESET_PIN) {
		printk(" (pin reset)");
	} else if (cause & supported & RESET_POR) {
		printk(" (power-on)");
	} else if (cause & supported & RESET_SOFTWARE) {
		printk(" (software)");
	} else if (cause == 0U) {
		printk(" (none / cleared)");
	} else {
		printk(" (other)");
	}
	printk("\n");
}

static void disconnect_conn(struct bt_conn *conn, void *data)
{
	ARG_UNUSED(data);
	(void)bt_conn_disconnect(conn, BT_HCI_ERR_REMOTE_USER_TERM_CONN);
}

static int stop_ble_activity(const struct shell *sh)
{
	int err;

	bt_conn_foreach(BT_CONN_TYPE_LE, disconnect_conn, NULL);

	err = bt_le_adv_stop();
	if (err && err != -EALREADY) {
		shell_warn(sh, "bt_le_adv_stop: %d", err);
		return err;
	}

	return 0;
}

static void idle_bypass_cb(const struct shell *sh, uint8_t *data, size_t len, void *user_data)
{
	ARG_UNUSED(user_data);

	if (len > 0U && data != NULL) {
		wake_src = SLEEP_WAKE_UART;
		idle_finish(sh);
	}
}

static int configure_sw0_sense(const struct shell *sh)
{
	int rc;

	if (!gpio_is_ready_dt(&sw0)) {
		shell_error(sh, "sw0 GPIO not ready");
		return -ENODEV;
	}

	rc = gpio_pin_configure_dt(&sw0, GPIO_INPUT);
	if (rc < 0) {
		shell_error(sh, "sw0 configure failed (%d)", rc);
		return rc;
	}

	/* PORT sense / LEVEL_ACTIVE — required for System OFF DETECT wake. */
	rc = gpio_pin_interrupt_configure_dt(&sw0, GPIO_INT_LEVEL_ACTIVE);
	if (rc < 0) {
		shell_error(sh, "sw0 sense interrupt failed (%d)", rc);
		return rc;
	}

	return 0;
}

static int enter_system_off(const struct shell *sh, int grtc_sec)
{
	int rc;

	shell_print(sh, "Preparing System OFF...");
	(void)stop_ble_activity(sh);

	rc = configure_sw0_sense(sh);
	if (rc) {
		return rc;
	}

	if (grtc_sec > 0) {
		rc = z_nrf_grtc_wakeup_prepare((uint64_t)grtc_sec * USEC_PER_SEC);
		if (rc < 0) {
			shell_error(sh, "GRTC wakeup prepare failed (%d)", rc);
			return rc;
		}
		shell_print(sh, "GRTC wake in %d s (also Button0)", grtc_sec);
	} else {
		shell_print(sh, "Press Button0 (sw0) to wake (device will reset)");
	}

	shell_print(sh, "Disabling USB CDC; shell drops until reboot");
	k_msleep(50);

	rc = usb_cdc_triple_disable();
	if (rc) {
		shell_warn(sh, "USB disable failed (%d); continuing", rc);
	}

#if DT_HAS_CHOSEN(zephyr_console)
	{
		const struct device *cons = DEVICE_DT_GET(DT_CHOSEN(zephyr_console));

		if (device_is_ready(cons)) {
			rc = pm_device_action_run(cons, PM_DEVICE_ACTION_SUSPEND);
			if (rc < 0 && rc != -ENOTSUP && rc != -EALREADY) {
				printk("console suspend failed (%d)\n", rc);
			}
		}
	}
#endif

	hwinfo_clear_reset_cause();
	sys_poweroff();

	/* Not reached on real System OFF. */
	return -EIO;
}

static int cmd_status(const struct shell *sh, size_t argc, char **argv)
{
	ARG_UNUSED(argc);
	ARG_UNUSED(argv);

	sleep_shell_print_reset_cause();

#if NRF_POWER_HAS_CONST_LATENCY && defined(POWER_CONSTLATSTAT_STATUS_Msk)
	shell_print(sh, "CONSTLAT: %s",
		    (NRF_POWER->CONSTLATSTAT & POWER_CONSTLATSTAT_STATUS_Msk) ?
			    "enabled" :
			    "disabled (LOWPWR default when idle)");
#else
	shell_print(sh, "CONSTLAT status register not available in this HAL build");
#endif

	shell_print(sh, "Wake tips:");
	shell_print(sh, "  sleep idle     — System ON idle; wake on CDC key or Button0");
	shell_print(sh, "  sleep off      — System OFF; wake on Button0 (reset)");
	shell_print(sh, "  sleep off grtc <s> — System OFF; GRTC and/or Button0");
	shell_print(sh, "CDC typing cannot wake System OFF (USB is off).");
	shell_print(sh, "J-Link attached: System OFF may be emulated.");

	return 0;
}

static int cmd_idle(const struct shell *sh, size_t argc, char **argv)
{
	ARG_UNUSED(argc);
	ARG_UNUSED(argv);

	/*
	 * Do not block the shell thread. Bypass RX is handled by shell_process()
	 * on that same thread (see Zephyr shell_thread / state_collect). Blocking
	 * here deadlocks CDC wake; match the shell "devmem load" pattern: arm
	 * bypass and return so the shell thread can drain RX.
	 */
	if (sleep_shell_is_quiesced()) {
		shell_warn(sh, "Already in System ON idle");
		return -EALREADY;
	}

	wake_src = SLEEP_WAKE_NONE;
	idle_sh = sh;
	set_quiesced(true);
	(void)stop_ble_activity(sh);

	shell_print(sh, "System ON idle: type a character or press Button0");
	shell_print(sh, "(BLE advertising stopped; use 'bt advertise on' after wake if needed)");
	shell_set_bypass(sh, idle_bypass_cb, NULL);

	return 0;
}

static int cmd_off(const struct shell *sh, size_t argc, char **argv)
{
	int grtc_sec = 0;

	if (argc >= 2) {
		if (strcmp(argv[1], "grtc") != 0 || argc < 3) {
			shell_error(sh, "usage: sleep off [grtc <seconds>]");
			return -EINVAL;
		}
		grtc_sec = (int)strtol(argv[2], NULL, 10);
		if (grtc_sec <= 0) {
			shell_error(sh, "grtc seconds must be > 0");
			return -EINVAL;
		}
	}

	set_quiesced(true);
	return enter_system_off(sh, grtc_sec);
}

static int cmd_constlat(const struct shell *sh, size_t argc, char **argv)
{
	ARG_UNUSED(argc);
	ARG_UNUSED(argv);

#if NRF_POWER_HAS_CONST_LATENCY
	nrf_power_task_trigger(NRF_POWER, NRF_POWER_TASK_CONSTLAT);
	shell_print(sh, "CONSTLAT enabled (higher idle current, fixed wake latency)");
	return 0;
#else
	shell_error(sh, "CONSTLAT not supported on this SoC build");
	return -ENOTSUP;
#endif
}

static int cmd_lowpwr(const struct shell *sh, size_t argc, char **argv)
{
	ARG_UNUSED(argc);
	ARG_UNUSED(argv);

#if NRF_POWER_HAS_LOW_POWER
	nrf_power_task_trigger(NRF_POWER, NRF_POWER_TASK_LOWPWR);
	shell_print(sh, "LOWPWR enabled (default System ON idle submode)");
	return 0;
#else
	shell_error(sh, "LOWPWR task not supported on this SoC build");
	return -ENOTSUP;
#endif
}

SHELL_STATIC_SUBCMD_SET_CREATE(sleep_cmds,
	SHELL_CMD(status, NULL, "Reset cause, CONSTLAT, wake tips", cmd_status),
	SHELL_CMD(idle, NULL, "System ON idle; wake on CDC or Button0", cmd_idle),
	SHELL_CMD_ARG(off, NULL, "System OFF [grtc <seconds>]", cmd_off, 1, 2),
	SHELL_CMD(constlat, NULL, "Enable constant-latency idle submode", cmd_constlat),
	SHELL_CMD(lowpwr, NULL, "Enable low-power idle submode", cmd_lowpwr),
	SHELL_SUBCMD_SET_END
);

SHELL_CMD_REGISTER(sleep, &sleep_cmds, "Sleep / System OFF test commands", NULL);
```

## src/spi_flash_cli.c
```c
/*
 * Copyright (c) 2026 Nordic Semiconductor ASA
 *
 * SPDX-License-Identifier: Apache-2.0
 *
 * Shell CLI for DK MX25R64 on SPI00. Uses a RAM spi_config so
 * `spiflash speed` can raise the CLI clock up to 32 MHz without
 * mutating the RO DTS spi_dt_spec used by the flash driver / MCUboot.
 */

#include <errno.h>
#include <stdlib.h>
#include <string.h>

#include <zephyr/device.h>
#include <zephyr/devicetree.h>
#include <zephyr/drivers/flash.h>
#include <zephyr/drivers/spi.h>
#include <zephyr/kernel.h>
#include <zephyr/shell/shell.h>
#include <zephyr/sys/byteorder.h>
#include <zephyr/sys/util.h>

#if !DT_NODE_HAS_STATUS(DT_NODELABEL(mx25r64), okay)
#error "mx25r64 must be enabled in the board overlay for spi_flash_cli"
#endif

#define SPI_FLASH_NODE DT_NODELABEL(mx25r64)

/* High offset on MX25 (OTA slot1 is internal RRAM, not this chip). */
#define SPI_FLASH_CLI_OFFSET 0xff000U
#define SPI_FLASH_CLI_SECTOR 4096U

#define SPI_FLASH_FREQ_MIN_HZ 1000000U
#define SPI_FLASH_FREQ_MAX_HZ 32000000U
#define SPI_FLASH_FREQ_DEFAULT_HZ 8000000U

#define SPI_NOR_CMD_WREN 0x06
#define SPI_NOR_CMD_RDSR 0x05
#define SPI_NOR_CMD_RDID 0x9F
#define SPI_NOR_CMD_READ 0x03
#define SPI_NOR_CMD_PP   0x02
#define SPI_NOR_CMD_SE   0x20
#define SPI_NOR_SR_WIP   BIT(0)

#define SPI_NOR_PAGE_SIZE 256U

static const struct spi_dt_spec flash_spi = SPI_DT_SPEC_GET(
	SPI_FLASH_NODE, SPI_OP_MODE_MASTER | SPI_WORD_SET(8) | SPI_TRANSFER_MSB, 0);

static struct spi_config cli_spi_cfg;
static bool cli_spi_ready;

static int cli_spi_init(void)
{
	if (cli_spi_ready) {
		return 0;
	}

	if (!spi_is_ready_dt(&flash_spi)) {
		return -ENODEV;
	}

	cli_spi_cfg = flash_spi.config;
	if (cli_spi_cfg.frequency == 0U) {
		cli_spi_cfg.frequency = SPI_FLASH_FREQ_DEFAULT_HZ;
	}
	cli_spi_ready = true;
	return 0;
}

static int spi_xfer(const struct spi_buf_set *tx, const struct spi_buf_set *rx)
{
	int err = cli_spi_init();

	if (err) {
		return err;
	}

	return spi_transceive(flash_spi.bus, &cli_spi_cfg, tx, rx);
}

static int spi_write_cmd(const uint8_t *cmd, size_t cmd_len)
{
	const struct spi_buf tx_buf = {
		.buf = (void *)cmd,
		.len = cmd_len,
	};
	const struct spi_buf_set tx = {
		.buffers = &tx_buf,
		.count = 1,
	};

	return spi_xfer(&tx, NULL);
}

static int spi_nor_wren(void)
{
	uint8_t cmd = SPI_NOR_CMD_WREN;

	return spi_write_cmd(&cmd, 1);
}

static int spi_nor_wait_ready(const struct shell *sh)
{
	for (int i = 0; i < 5000; i++) {
		uint8_t cmd = SPI_NOR_CMD_RDSR;
		uint8_t sr = 0xff;
		const struct spi_buf tx_bufs[] = {
			{ .buf = &cmd, .len = 1 },
			{ .buf = NULL, .len = 1 },
		};
		const struct spi_buf rx_bufs[] = {
			{ .buf = NULL, .len = 1 },
			{ .buf = &sr, .len = 1 },
		};
		const struct spi_buf_set tx = { .buffers = tx_bufs, .count = 2 };
		const struct spi_buf_set rx = { .buffers = rx_bufs, .count = 2 };
		int err = spi_xfer(&tx, &rx);

		if (err) {
			return err;
		}
		if ((sr & SPI_NOR_SR_WIP) == 0) {
			return 0;
		}
		k_msleep(1);
	}

	shell_error(sh, "flash busy timeout");
	return -ETIMEDOUT;
}

static int spi_nor_rdid(uint8_t id[3])
{
	uint8_t cmd = SPI_NOR_CMD_RDID;
	const struct spi_buf tx_bufs[] = {
		{ .buf = &cmd, .len = 1 },
		{ .buf = NULL, .len = 3 },
	};
	const struct spi_buf rx_bufs[] = {
		{ .buf = NULL, .len = 1 },
		{ .buf = id, .len = 3 },
	};
	const struct spi_buf_set tx = { .buffers = tx_bufs, .count = 2 };
	const struct spi_buf_set rx = { .buffers = rx_bufs, .count = 2 };

	return spi_xfer(&tx, &rx);
}

static int spi_nor_read(uint32_t addr, uint8_t *data, size_t len)
{
	uint8_t cmd[4] = {
		SPI_NOR_CMD_READ,
		(addr >> 16) & 0xff,
		(addr >> 8) & 0xff,
		addr & 0xff,
	};
	const struct spi_buf tx_bufs[] = {
		{ .buf = cmd, .len = sizeof(cmd) },
		{ .buf = NULL, .len = len },
	};
	const struct spi_buf rx_bufs[] = {
		{ .buf = NULL, .len = sizeof(cmd) },
		{ .buf = data, .len = len },
	};
	const struct spi_buf_set tx = { .buffers = tx_bufs, .count = 2 };
	const struct spi_buf_set rx = { .buffers = rx_bufs, .count = 2 };

	return spi_xfer(&tx, &rx);
}

static int spi_nor_erase_sector(const struct shell *sh, uint32_t addr)
{
	uint8_t cmd[4] = {
		SPI_NOR_CMD_SE,
		(addr >> 16) & 0xff,
		(addr >> 8) & 0xff,
		addr & 0xff,
	};
	int err = spi_nor_wren();

	if (err) {
		return err;
	}
	err = spi_write_cmd(cmd, sizeof(cmd));
	if (err) {
		return err;
	}
	return spi_nor_wait_ready(sh);
}

static int spi_nor_page_program(const struct shell *sh, uint32_t addr,
				const uint8_t *data, size_t len)
{
	uint8_t hdr[4] = {
		SPI_NOR_CMD_PP,
		(addr >> 16) & 0xff,
		(addr >> 8) & 0xff,
		addr & 0xff,
	};
	const struct spi_buf tx_bufs[] = {
		{ .buf = hdr, .len = sizeof(hdr) },
		{ .buf = (void *)data, .len = len },
	};
	const struct spi_buf_set tx = { .buffers = tx_bufs, .count = 2 };
	int err = spi_nor_wren();

	if (err) {
		return err;
	}
	err = spi_xfer(&tx, NULL);
	if (err) {
		return err;
	}
	return spi_nor_wait_ready(sh);
}

static int cmd_speed(const struct shell *sh, size_t argc, char **argv)
{
	int err = cli_spi_init();

	if (err) {
		shell_error(sh, "SPI not ready (%d)", err);
		return err;
	}

	if (argc == 1) {
		shell_print(sh, "CLI SPI frequency: %u Hz (DTS flash driver stays at %u Hz)",
			    cli_spi_cfg.frequency,
			    flash_spi.config.frequency ? flash_spi.config.frequency
						       : SPI_FLASH_FREQ_DEFAULT_HZ);
		return 0;
	}

	char *end = NULL;
	unsigned long hz = strtoul(argv[1], &end, 0);

	if (end == argv[1] || *end != '\0') {
		shell_error(sh, "invalid frequency");
		return -EINVAL;
	}
	if (hz < SPI_FLASH_FREQ_MIN_HZ || hz > SPI_FLASH_FREQ_MAX_HZ) {
		shell_error(sh, "frequency must be %u..%u Hz",
			    SPI_FLASH_FREQ_MIN_HZ, SPI_FLASH_FREQ_MAX_HZ);
		return -EINVAL;
	}

	cli_spi_cfg.frequency = (uint32_t)hz;
	shell_print(sh, "CLI SPI frequency set to %u Hz", cli_spi_cfg.frequency);
	shell_print(sh, "Note: >8 MHz may need high-drive GPIOs; validate with spiflash id/test");
	return 0;
}

static int cmd_id(const struct shell *sh, size_t argc, char **argv)
{
	uint8_t id[3];
	int err;

	ARG_UNUSED(argc);
	ARG_UNUSED(argv);

	err = spi_nor_rdid(id);
	if (err) {
		shell_error(sh, "RDID failed (%d) @ %u Hz", err, cli_spi_cfg.frequency);
		return err;
	}

	shell_print(sh, "JEDEC ID: %02x %02x %02x @ %u Hz", id[0], id[1], id[2],
		    cli_spi_cfg.frequency);
	if (id[0] == 0xc2 && id[1] == 0x28 && id[2] == 0x17) {
		shell_print(sh, "matches MX25R64");
	}
	return 0;
}

static int cmd_erase(const struct shell *sh, size_t argc, char **argv)
{
	int err;

	ARG_UNUSED(argc);
	ARG_UNUSED(argv);

	err = spi_nor_erase_sector(sh, SPI_FLASH_CLI_OFFSET);
	if (err) {
		shell_error(sh, "erase failed (%d)", err);
		return err;
	}
	shell_print(sh, "erased 4 KiB @ 0x%08x @ %u Hz", SPI_FLASH_CLI_OFFSET,
		    cli_spi_cfg.frequency);
	return 0;
}

static int cmd_write(const struct shell *sh, size_t argc, char **argv)
{
	static const uint8_t pattern[] = { 0x55, 0xaa, 0x66, 0x99, 0x12, 0x34, 0x56, 0x78 };
	int err;

	ARG_UNUSED(argc);
	ARG_UNUSED(argv);

	err = spi_nor_page_program(sh, SPI_FLASH_CLI_OFFSET, pattern, sizeof(pattern));
	if (err) {
		shell_error(sh, "program failed (%d)", err);
		return err;
	}
	shell_print(sh, "wrote %u bytes @ 0x%08x @ %u Hz", (unsigned)sizeof(pattern),
		    SPI_FLASH_CLI_OFFSET, cli_spi_cfg.frequency);
	return 0;
}

static int cmd_read(const struct shell *sh, size_t argc, char **argv)
{
	uint8_t buf[16];
	int err;

	ARG_UNUSED(argc);
	ARG_UNUSED(argv);

	err = spi_nor_read(SPI_FLASH_CLI_OFFSET, buf, sizeof(buf));
	if (err) {
		shell_error(sh, "read failed (%d)", err);
		return err;
	}

	shell_fprintf(sh, SHELL_NORMAL, "read @ 0x%08x @ %u Hz:", SPI_FLASH_CLI_OFFSET,
		      cli_spi_cfg.frequency);
	for (size_t i = 0; i < sizeof(buf); i++) {
		shell_fprintf(sh, SHELL_NORMAL, " %02x", buf[i]);
	}
	shell_print(sh, "");
	return 0;
}

static int cmd_test(const struct shell *sh, size_t argc, char **argv)
{
	static const uint8_t expected[] = { 0x55, 0xaa, 0x66, 0x99 };
	uint8_t buf[sizeof(expected)];
	int err;

	ARG_UNUSED(argc);
	ARG_UNUSED(argv);

	shell_print(sh, "SPI flash R/W test @ 0x%08x, %u Hz", SPI_FLASH_CLI_OFFSET,
		    cli_spi_cfg.frequency);

	err = spi_nor_erase_sector(sh, SPI_FLASH_CLI_OFFSET);
	if (err) {
		shell_error(sh, "erase failed (%d)", err);
		return err;
	}

	memset(buf, 0, sizeof(buf));
	err = spi_nor_read(SPI_FLASH_CLI_OFFSET, buf, sizeof(buf));
	if (err) {
		shell_error(sh, "read-after-erase failed (%d)", err);
		return err;
	}
	for (size_t i = 0; i < sizeof(buf); i++) {
		if (buf[i] != 0xff) {
			shell_error(sh, "erase verify fail at +%u: %02x", (unsigned)i, buf[i]);
			return -EIO;
		}
	}

	err = spi_nor_page_program(sh, SPI_FLASH_CLI_OFFSET, expected, sizeof(expected));
	if (err) {
		shell_error(sh, "program failed (%d)", err);
		return err;
	}

	memset(buf, 0, sizeof(buf));
	err = spi_nor_read(SPI_FLASH_CLI_OFFSET, buf, sizeof(buf));
	if (err) {
		shell_error(sh, "read-after-write failed (%d)", err);
		return err;
	}
	if (memcmp(expected, buf, sizeof(expected)) != 0) {
		shell_error(sh, "data mismatch");
		return -EIO;
	}

	shell_print(sh, "pass");
	return 0;
}

static int cmd_info(const struct shell *sh, size_t argc, char **argv)
{
	const struct device *flash_dev = DEVICE_DT_GET(SPI_FLASH_NODE);

	ARG_UNUSED(argc);
	ARG_UNUSED(argv);

	(void)cli_spi_init();

	shell_print(sh, "device: %s ready=%d", flash_dev->name, device_is_ready(flash_dev));
	shell_print(sh, "CLI offset: 0x%08x (sector %u)", SPI_FLASH_CLI_OFFSET,
		    SPI_FLASH_CLI_SECTOR);
	shell_print(sh, "CLI freq: %u Hz (max %u)",
		    cli_spi_ready ? cli_spi_cfg.frequency : 0U, SPI_FLASH_FREQ_MAX_HZ);
	shell_print(sh, "DTS spi-max-frequency: %u Hz",
		    flash_spi.config.frequency ? flash_spi.config.frequency
					       : SPI_FLASH_FREQ_DEFAULT_HZ);
	return 0;
}

SHELL_STATIC_SUBCMD_SET_CREATE(
	spiflash_cmds,
	SHELL_CMD(info, NULL, "Show SPI flash CLI info", cmd_info),
	SHELL_CMD(id, NULL, "Read JEDEC ID at CLI SPI speed", cmd_id),
	SHELL_CMD_ARG(speed, NULL, "Get/set CLI SPI Hz (1e6..32e6)", cmd_speed, 1, 1),
	SHELL_CMD(erase, NULL, "Erase CLI test sector", cmd_erase),
	SHELL_CMD(write, NULL, "Program test pattern in CLI sector", cmd_write),
	SHELL_CMD(read, NULL, "Read 16 bytes from CLI sector", cmd_read),
	SHELL_CMD(test, NULL, "Erase/write/read verify at CLI speed", cmd_test),
	SHELL_SUBCMD_SET_END);

SHELL_CMD_REGISTER(spiflash, &spiflash_cmds, "SPI00 MX25R64 flash CLI", NULL);
```
